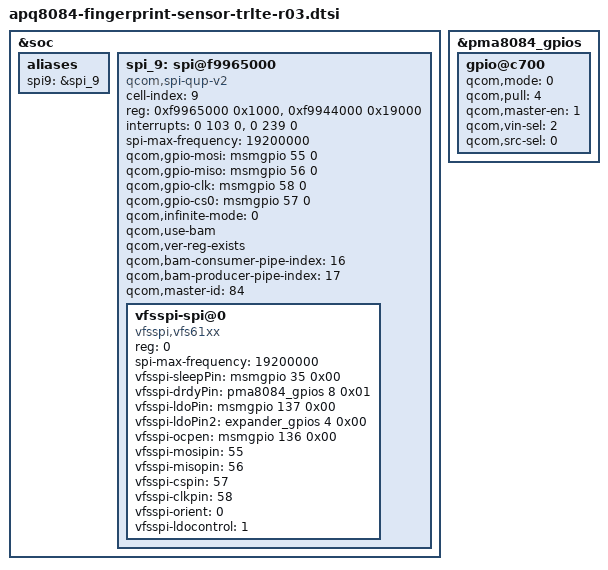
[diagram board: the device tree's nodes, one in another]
/* Copyright (c) 2013-2014, The Linux Foundation. All rights reserved.
 *
 * This program is free software; you can redistribute it and/or modify
 * it under the terms of the GNU General Public License version 2 and
 * only version 2 as published by the Free Software Foundation.
 *
 * This program is distributed in the hope that it will be useful,
 * but WITHOUT ANY WARRANTY; without even the implied warranty of
 * MERCHANTABILITY or FITNESS FOR A PARTICULAR PURPOSE.  See the
 * GNU General Public License for more details.
 */

/*
 * This dtsi is for fingerprint sensor. (rev.03 ~ rev.09)
 */
&soc {
	aliases {
		spi9 = &spi_9;
	};

	spi_9: spi@f9965000 {
		compatible = "qcom,spi-qup-v2";
		cell-index = <9>;
		#address-cells = <1>;
		#size-cells = <0>;
		reg = <0xf9965000 0x1000>,
			<0xf9944000 0x19000>;
		reg-names = "spi_physical", "spi_bam_physical";
		interrupt-names = "spi_irq", "spi_bam_irq";
		interrupts = <0 103 0>, <0 239 0>;
		spi-max-frequency = <19200000>;

		qcom,gpio-mosi = <&msmgpio 55 0>;
		qcom,gpio-miso = <&msmgpio 56 0>;
		qcom,gpio-clk  = <&msmgpio 58 0>;
		qcom,gpio-cs0  = <&msmgpio 57 0>;

		qcom,infinite-mode = <0>;
		qcom,use-bam;
		qcom,ver-reg-exists;
		qcom,bam-consumer-pipe-index = <16>;
		qcom,bam-producer-pipe-index = <17>;

		qcom,master-id = <84>;

		vfsspi-spi@0 {
			compatible = "vfsspi,vfs61xx";
			reg = <0>;
			spi-max-frequency = <19200000>;
			vfsspi-sleepPin = <&msmgpio 35 0x00>;
			vfsspi-drdyPin = <&pma8084_gpios 8 0x01>;
			vfsspi-ldoPin = <&msmgpio 137 0x00>;
			vfsspi-ldoPin2 = <&expander_gpios 4 0x00>;
			/* vfsspi-ocpflag = <&msmgpio 144 0x00>; */
			vfsspi-ocpen = <&msmgpio 136 0x00>;
			vfsspi-mosipin = <55>;
			vfsspi-misopin = <56>;
			vfsspi-cspin = <57>;
			vfsspi-clkpin = <58>;
			vfsspi-orient = <0>;
			vfsspi-ldocontrol= <1>;
		};
	};

};

&pma8084_gpios {
	gpio@c700 { /* GPIO 8 */
		/* BTP_IRQ */
		qcom,mode = <0>;		/* Digital input */
		qcom,pull = <4>;         /* Pull down */
		qcom,master-en = <1>;
		qcom,vin-sel = <2>;		/* select 1.8 V source */
		qcom,src-sel = <0>;
	};
};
